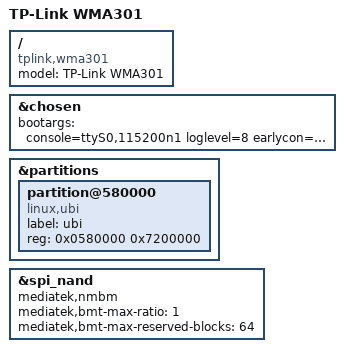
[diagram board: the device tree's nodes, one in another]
// SPDX-License-Identifier: GPL-2.0-or-later OR MIT

/dts-v1/;
#include <dt-bindings/gpio/gpio.h>
#include <dt-bindings/input/input.h>
#include <dt-bindings/leds/common.h>

#include "mt7981b-tplink-wma301-common.dtsi"

/ {
	model = "TP-Link WMA301";
	compatible = "tplink,wma301", "mediatek,mt7981";
};

&chosen {
	bootargs = "console=ttyS0,115200n1 loglevel=8 earlycon=uart8250,mmio32,0x11002000";
};

&partitions {
	partition@580000 {
		label = "ubi";
		compatible = "linux,ubi";
		reg = <0x0580000 0x7200000>;
	};
};

&spi_nand {
	mediatek,nmbm;
	mediatek,bmt-max-ratio = <1>;
	mediatek,bmt-max-reserved-blocks = <64>;
};
